# MU3E_FULL8LANE_TYPE0_SYSTEM_SC_HUB register map
Vendor: Mu3e; Series: MU3E_FULL8LANE_TYPE0; File version: 2026.05.06
Registers are 32-bit, read-write, reset 0x0 unless marked. A register's access mark holds for its fields unless they carry their own. Offsets are from the block's base; [hi:lo] are bit positions; 'fields as' and 'values as' point back to an identical list.

## DATA_PATH_SUBSYSTEM_ARB_HIT_TYPE0_SUPERCORE_0_LANE_0_CSR — Datapath-local slave expanded below the SC-hub mm_bridge.s0 aperture. Qsys slave data_path_subsystem_arb_hit_type0_supercore_0_lane_0.csr is SC-hub-relative at 0x00022280 with compiled aperture size 0x00000080. Compiled Qsys module lane_0 kind=arb_hit_type0 version=26.4.0.505 from arb_hit_type0_supercore.qsys. Version/identity parameters: VERSION_MAJOR=26, VERSION_MINOR=4, VERSION_PATCH=0, BUILD=505, VERSION_DATE=20260505, VERSION_GIT=0, IP_UID=1095263280, INSTANCE_ID=0. No source SVD file was present; this peripheral is generated as an explicitly raw window. This peripheral is generated from misc/arb_hit_type0/rtl/arb_hit_type0_csr.sv and the per-lane Qsys child instances in arb_hit_type0_supercore.qsys; no standalone source SVD was present.
Base 0x00022280
Same registers: DATA_PATH_SUBSYSTEM_ARB_HIT_TYPE0_SUPERCORE_0_LANE_1_CSR 0x00022300, DATA_PATH_SUBSYSTEM_ARB_HIT_TYPE0_SUPERCORE_0_LANE_2_CSR 0x00022380, DATA_PATH_SUBSYSTEM_ARB_HIT_TYPE0_SUPERCORE_0_LANE_3_CSR 0x00022400, DATA_PATH_SUBSYSTEM_ARB_HIT_TYPE0_SUPERCORE_0_LANE_4_CSR 0x00022480, DATA_PATH_SUBSYSTEM_ARB_HIT_TYPE0_SUPERCORE_0_LANE_5_CSR 0x00022500, DATA_PATH_SUBSYSTEM_ARB_HIT_TYPE0_SUPERCORE_0_LANE_6_CSR 0x00022580, DATA_PATH_SUBSYSTEM_ARB_HIT_TYPE0_SUPERCORE_0_LANE_7_CSR 0x00022600
0x00 UID ro reset 0x41485430 — Software-visible hit-type0 arbiter UID. Default ASCII "AHT0" (0x41485430).
  [31:0] value — Compile-time or integration-time UID word.
0x04 META — Read-multiplexed metadata word. Write page[1:0] before reading back: 0=VERSION, 1=VERSION_DATE, 2=VERSION_GIT, 3=INSTANCE_ID.
  [1:0] page — Selects the metadata read page.
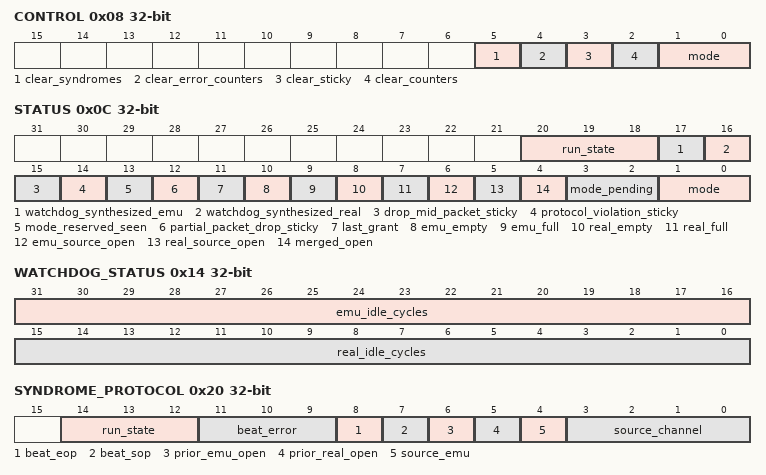
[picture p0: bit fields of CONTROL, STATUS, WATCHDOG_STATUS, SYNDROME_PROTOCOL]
0x08 CONTROL — Mode request and write-one clear controls.
  [5] clear_syndromes — Write 1 to clear captured syndrome words.
  [4] clear_error_counters — Write 1 to clear protocol and drop-mid-packet error counters.
  [3] clear_sticky — Write 1 to clear sticky status bits.
  [2] clear_counters — Write 1 to clear hit/frame/drop counters and high-word snapshots.
  [1:0] mode — 0=real source, 1=emulator source, 2=mixed round-robin; 3 is reserved and sanitizes to real mode.
0x0C STATUS ro — Live source, FIFO, mode, sticky-error, watchdog, and run-state summary.
  [20:18] run_state — Run-control state sampled by the arbiter.
  [17] watchdog_synthesized_emu — Emulator-source watchdog synthesized a frame boundary.
  [16] watchdog_synthesized_real — Real-source watchdog synthesized a frame boundary.
  [15] drop_mid_packet_sticky — Sticky mid-packet drop flag.
  [14] protocol_violation_sticky — Sticky protocol violation flag.
  [13] mode_reserved_seen — Sticky flag that software requested reserved mode 3.
  [12] partial_packet_drop_sticky — Sticky flag for a drop while an ingress packet was open.
  [11] last_grant — Last round-robin grant source.
  [10] emu_empty — Emulator-source FIFO empty.
  [9] emu_full — Emulator-source FIFO full.
  [8] real_empty — Real-source FIFO empty.
  [7] real_full — Real-source FIFO full.
  [6] emu_source_open — Emulator-source packet is open on egress.
  [5] real_source_open — Real-source packet is open on egress.
  [4] merged_open — Merged egress packet is currently open.
  [3:2] mode_pending — Requested source selection mode waiting for commit.
  [1:0] mode — Committed source selection mode.
0x10 WATCHDOG_CYCLES — Frame-boundary watchdog threshold in clock cycles.
  [15:0] cycles — Watchdog threshold.
0x14 WATCHDOG_STATUS ro — Current source idle counters used by the watchdog.
  [31:16] emu_idle_cycles — Emulator-source idle-cycle count.
  [15:0] real_idle_cycles — Real-source idle-cycle count.
0x18 ERROR_COUNT_PROTOCOL ro — Saturating protocol-event counter.
  [31:0] value — Protocol error count.
0x1C ERROR_COUNT_DROP_MID_PACKET ro — Saturating mid-packet-drop event counter.
  [31:0] value — Drop-mid-packet error count.
0x20 SYNDROME_PROTOCOL ro — First captured protocol-event syndrome until cleared.
  [14:12] run_state — Run-control state at capture.
  [11:9] beat_error — Avalon-ST error sideband on the selected beat.
  [8] beat_eop — End-of-packet sideband on the selected beat.
  [7] beat_sop — Start-of-packet sideband on the selected beat.
  [6] prior_emu_open — Emulator-source open state before the event.
  [5] prior_real_open — Real-source open state before the event.
  [4] source_emu — 1 when the syndrome came from the emulator source.
  [3:0] source_channel — Channel on the selected source.
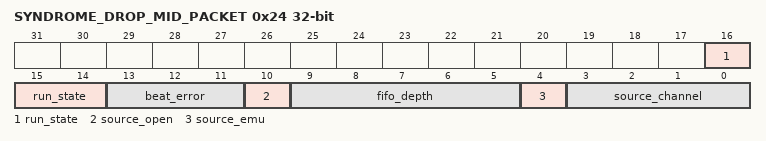
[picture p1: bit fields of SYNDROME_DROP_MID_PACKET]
0x24 SYNDROME_DROP_MID_PACKET ro — First captured mid-packet-drop syndrome until cleared.
  [16:14] run_state — Run-control state at capture.
  [13:11] beat_error — Avalon-ST error sideband at capture.
  [10] source_open — Source egress-open state at capture.
  [9:5] fifo_depth — Source FIFO depth at capture.
  [4] source_emu — 1 when the syndrome came from the emulator source.
  [3:0] source_channel — Ingress source channel.
0x28 INGRESS_REAL_HITS_LO ro — Accepted real-source hit beats. Reading the low word snapshots the matching high word into the following HI_SNAPSHOT register.
  [31:0] low — Low 32 bits of the saturating 64-bit counter.
0x2C INGRESS_REAL_HITS_HI_SNAPSHOT ro — High 32-bit snapshot captured by the preceding low-word counter read.
  [31:0] high — Snapshot high 32 bits of the saturating 64-bit counter.
0x30 INGRESS_EMU_HITS_LO ro — Accepted emulator-source hit beats. Reading the low word snapshots the matching high word into the following HI_SNAPSHOT register.
  [31:0] low — Low 32 bits of the saturating 64-bit counter.
0x34 INGRESS_EMU_HITS_HI_SNAPSHOT ro — High 32-bit snapshot captured by the preceding low-word counter read.
  fields as INGRESS_REAL_HITS_HI_SNAPSHOT
0x38 DROPS_REAL_LO ro — Dropped real-source beats. Reading the low word snapshots the matching high word into the following HI_SNAPSHOT register.
  [31:0] low — Low 32 bits of the saturating 64-bit counter.
0x3C DROPS_REAL_HI_SNAPSHOT ro — High 32-bit snapshot captured by the preceding low-word counter read.
  fields as INGRESS_REAL_HITS_HI_SNAPSHOT
0x40 DROPS_EMU_LO ro — Dropped emulator-source beats. Reading the low word snapshots the matching high word into the following HI_SNAPSHOT register.
  [31:0] low — Low 32 bits of the saturating 64-bit counter.
0x44 DROPS_EMU_HI_SNAPSHOT ro — High 32-bit snapshot captured by the preceding low-word counter read.
  fields as INGRESS_REAL_HITS_HI_SNAPSHOT
0x48 EGRESS_REAL_HITS_LO ro — Granted real-source egress hit beats, excluding synthesized frames. Reading the low word snapshots the matching high word into the following HI_SNAPSHOT register.
  [31:0] low — Low 32 bits of the saturating 64-bit counter.
0x4C EGRESS_REAL_HITS_HI_SNAPSHOT ro — High 32-bit snapshot captured by the preceding low-word counter read.
  fields as INGRESS_REAL_HITS_HI_SNAPSHOT
0x50 EGRESS_EMU_HITS_LO ro — Granted emulator-source egress hit beats, excluding synthesized frames. Reading the low word snapshots the matching high word into the following HI_SNAPSHOT register.
  [31:0] low — Low 32 bits of the saturating 64-bit counter.
0x54 EGRESS_EMU_HITS_HI_SNAPSHOT ro — High 32-bit snapshot captured by the preceding low-word counter read.
  fields as INGRESS_REAL_HITS_HI_SNAPSHOT
0x58 INGRESS_REAL_FRAMES_LO ro — Accepted real-source frame boundaries. Reading the low word snapshots the matching high word into the following HI_SNAPSHOT register.
  [31:0] low — Low 32 bits of the saturating 64-bit counter.
0x5C INGRESS_REAL_FRAMES_HI_SNAPSHOT ro — High 32-bit snapshot captured by the preceding low-word counter read.
  fields as INGRESS_REAL_HITS_HI_SNAPSHOT
0x60 INGRESS_EMU_FRAMES_LO ro — Accepted emulator-source frame boundaries. Reading the low word snapshots the matching high word into the following HI_SNAPSHOT register.
  [31:0] low — Low 32 bits of the saturating 64-bit counter.
0x64 INGRESS_EMU_FRAMES_HI_SNAPSHOT ro — High 32-bit snapshot captured by the preceding low-word counter read.
  fields as INGRESS_REAL_HITS_HI_SNAPSHOT
0x68 EGRESS_REAL_FRAMES_LO ro — Real-source egress frame boundaries. Reading the low word snapshots the matching high word into the following HI_SNAPSHOT register.
  [31:0] low — Low 32 bits of the saturating 64-bit counter.
0x6C EGRESS_REAL_FRAMES_HI_SNAPSHOT ro — High 32-bit snapshot captured by the preceding low-word counter read.
  fields as INGRESS_REAL_HITS_HI_SNAPSHOT
0x70 EGRESS_EMU_FRAMES_LO ro — Emulator-source egress frame boundaries. Reading the low word snapshots the matching high word into the following HI_SNAPSHOT register.
  [31:0] low — Low 32 bits of the saturating 64-bit counter.
0x74 EGRESS_EMU_FRAMES_HI_SNAPSHOT ro — High 32-bit snapshot captured by the preceding low-word counter read.
  fields as INGRESS_REAL_HITS_HI_SNAPSHOT
